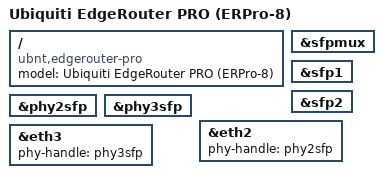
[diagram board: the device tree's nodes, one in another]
// SPDX-License-Identifier: GPL-2.0-or-later OR MIT

#include "cn6120_ubnt_e20x.dtsi"

/ {
	/* E200 */
	compatible = "ubnt,edgerouter-pro", "ubnt,e200", "cavium,cn61xx";
	model = "Ubiquiti EdgeRouter PRO (ERPro-8)";
};

&sfpmux {
	status = "okay";
};

&sfp1 {
	status = "okay";
};

&sfp2 {
	status = "okay";
};

&phy2sfp {
	status = "okay";
};

&phy3sfp {
	status = "okay";
};

&eth2 {
	phy-handle = <&phy2sfp>;
};

&eth3 {
	phy-handle = <&phy3sfp>;
};
